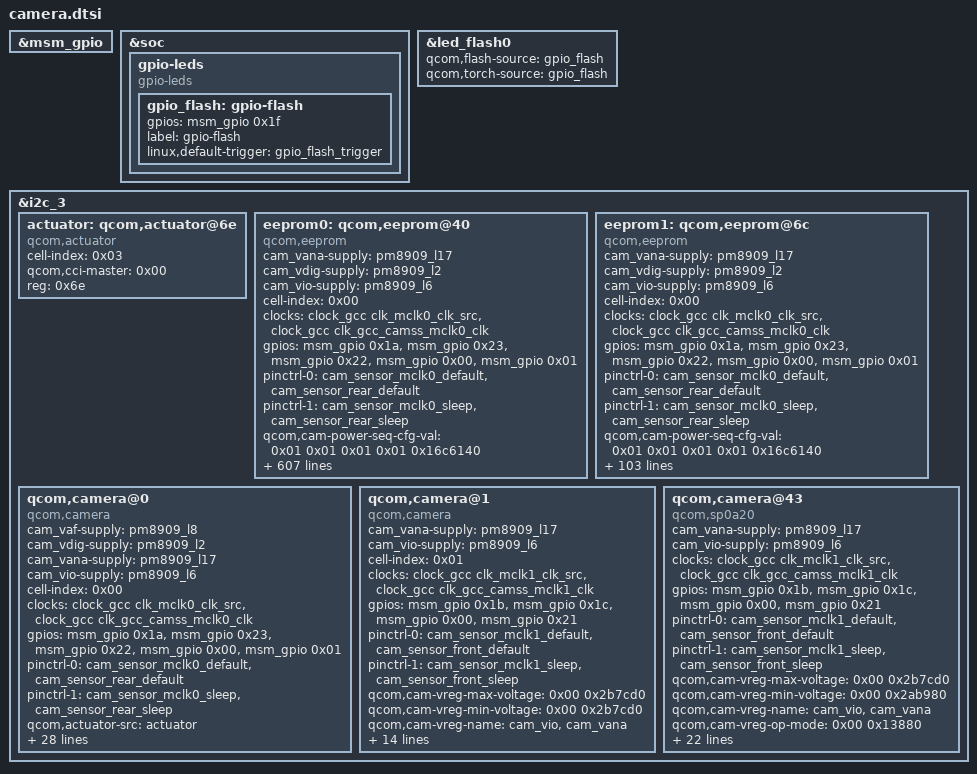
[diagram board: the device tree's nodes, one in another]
&msm_gpio {
	/delete-node/ SL610W1D_pins;
};

&soc {
	/delete-node/ flashlight;

	gpio-leds {
		compatible = "gpio-leds";
		status = "ok";

		gpio_flash: gpio-flash {
			gpios = <&msm_gpio 0x1f 0x00>;
			label = "gpio-flash";
			linux,default-trigger = "gpio_flash_trigger";
		};
	};
};

&led_flash0 {
	qcom,flash-source = <&gpio_flash>;
	qcom,torch-source = <&gpio_flash>;
};

&i2c_3 {
	/delete-node/ qcom,camera@0;
	/delete-node/ qcom,camera@1;
	/delete-node/ qcom,camera@42;

	actuator: qcom,actuator@6e {
		cell-index = <0x03>;
		compatible = "qcom,actuator";
		qcom,cci-master = <0x00>;
		reg = <0x6e>;
	};

	eeprom0: qcom,eeprom@40 {
		cam_vana-supply = <&pm8909_l17>;
		cam_vdig-supply = <&pm8909_l2>;
		cam_vio-supply = <&pm8909_l6>;
		cell-index = <0x00>;
		clock-names = "cam_src_clk", "cam_clk";
		clocks = <&clock_gcc clk_mclk0_clk_src>,
				<&clock_gcc clk_gcc_camss_mclk0_clk>;
		compatible = "qcom,eeprom";
		gpios = <&msm_gpio 0x1a 0x00 &msm_gpio 0x23 0x00 &msm_gpio 0x22 0x00 &msm_gpio 0x00 0x00 &msm_gpio 0x01 0x00>;
		pinctrl-0 = <&cam_sensor_mclk0_default
				&cam_sensor_rear_default>;
		pinctrl-1 = <&cam_sensor_mclk0_sleep &cam_sensor_rear_sleep>;
		pinctrl-names = "cam_default", "cam_suspend";
		qcom,cam-power-seq-cfg-val = <0x01 0x01 0x01 0x01 0x16c6140>;
		qcom,cam-power-seq-delay = <0x01 0x0a 0x0a 0x05 0x05>;
		qcom,cam-power-seq-type = "sensor_vreg", "sensor_gpio", "sensor_gpio", "sensor_gpio", "sensor_clk";
		qcom,cam-power-seq-val = "cam_vdig", "sensor_gpio_vana", "sensor_gpio_reset", "sensor_gpio_standby", "sensor_cam_mclk";
		qcom,cam-vreg-max-voltage = <0x124f80 0x00 0x2b7cd0>;
		qcom,cam-vreg-min-voltage = <0x124f80 0x00 0x2b7cd0>;
		qcom,cam-vreg-name = "cam_vdig", "cam_vio", "cam_vana";
		qcom,cam-vreg-op-mode = <0x30d40 0x00 0x13880>;
		qcom,cam-vreg-type = <0x00 0x01 0x00>;
		qcom,cci-master = <0x00>;
		qcom,eeprom-name = "hynix_hi841";
		qcom,gpio-req-tbl-flags = <0x01 0x00 0x00 0x00 0x00>;
		qcom,gpio-req-tbl-label = "CAMIF_MCLK", "CAM_RESET1", "CAM_STANDBY", "CAM_VANA", "CAM_VDIG";
		qcom,gpio-req-tbl-num = <0x00 0x01 0x02 0x03 0x04>;
		qcom,gpio-reset = <0x01>;
		qcom,gpio-standby = <0x02>;
		qcom,gpio-vana = <0x03>;
		qcom,gpio-vdig = <0x04>;
		qcom,mem0 = <0x00 0x00 0x02 0x00 0x01 0x00>;
		qcom,mem1 = <0x00 0x00 0x02 0x00 0x01 0x00>;
		qcom,mem10 = <0x01 0xa000 0x02 0x00 0x01 0x00>;
		qcom,mem100 = <0x00 0x00 0x02 0x00 0x01 0x00>;
		qcom,mem101 = <0x00 0x00 0x02 0x00 0x01 0x00>;
		qcom,mem102 = <0x00 0x00 0x02 0x00 0x01 0x00>;
		qcom,mem103 = <0x01 0xa000 0x02 0x00 0x01 0x00>;
		qcom,mem104 = <0x00 0x00 0x02 0x00 0x01 0x00>;
		qcom,mem105 = <0x00 0x00 0x02 0x00 0x01 0x00>;
		qcom,mem106 = <0x00 0x00 0x02 0x00 0x01 0x00>;
		qcom,mem107 = <0x01 0xa000 0x02 0x00 0x01 0x00>;
		qcom,mem108 = <0x00 0x00 0x02 0x00 0x01 0x00>;
		qcom,mem109 = <0x00 0x00 0x02 0x00 0x01 0x00>;
		qcom,mem11 = <0x00 0x00 0x02 0x00 0x01 0x00>;
		qcom,mem110 = <0x00 0x00 0x02 0x00 0x01 0x00>;
		qcom,mem111 = <0x01 0xa000 0x02 0x00 0x01 0x00>;
		qcom,mem112 = <0x00 0x00 0x02 0x00 0x01 0x00>;
		qcom,mem113 = <0x00 0x00 0x02 0x00 0x01 0x00>;
		qcom,mem114 = <0x00 0x00 0x02 0x00 0x01 0x00>;
		qcom,mem115 = <0x01 0xa000 0x02 0x00 0x01 0x00>;
		qcom,mem116 = <0x00 0x00 0x02 0x00 0x01 0x00>;
		qcom,mem117 = <0x00 0x00 0x02 0x00 0x01 0x00>;
		qcom,mem118 = <0x00 0x00 0x02 0x00 0x01 0x00>;
		qcom,mem119 = <0x01 0xa000 0x02 0x00 0x01 0x00>;
		qcom,mem12 = <0x00 0x00 0x02 0x00 0x01 0x00>;
		qcom,mem120 = <0x00 0x00 0x02 0x00 0x01 0x00>;
		qcom,mem121 = <0x00 0x00 0x02 0x00 0x01 0x00>;
		qcom,mem122 = <0x00 0x00 0x02 0x00 0x01 0x00>;
		qcom,mem123 = <0x01 0xa000 0x02 0x00 0x01 0x00>;
		qcom,mem124 = <0x00 0x00 0x02 0x00 0x01 0x00>;
		qcom,mem125 = <0x00 0x00 0x02 0x00 0x01 0x00>;
		qcom,mem126 = <0x00 0x00 0x02 0x00 0x01 0x00>;
		qcom,mem127 = <0x01 0xa000 0x02 0x00 0x01 0x00>;
		qcom,mem128 = <0x00 0x00 0x02 0x00 0x01 0x00>;
		qcom,mem129 = <0x00 0x00 0x02 0x00 0x01 0x00>;
		qcom,mem13 = <0x00 0x00 0x02 0x00 0x01 0x00>;
		qcom,mem130 = <0x00 0x00 0x02 0x00 0x01 0x00>;
		qcom,mem131 = <0x01 0xa000 0x02 0x00 0x01 0x00>;
		qcom,mem132 = <0x00 0x00 0x02 0x00 0x01 0x00>;
		qcom,mem133 = <0x00 0x00 0x02 0x00 0x01 0x00>;
		qcom,mem134 = <0x00 0x00 0x02 0x00 0x01 0x00>;
		qcom,mem135 = <0x01 0xa000 0x02 0x00 0x01 0x00>;
		qcom,mem136 = <0x00 0x00 0x02 0x00 0x01 0x00>;
		qcom,mem137 = <0x00 0x00 0x02 0x00 0x01 0x00>;
		qcom,mem138 = <0x00 0x00 0x02 0x00 0x01 0x00>;
		qcom,mem139 = <0x01 0xa000 0x02 0x00 0x01 0x00>;
		qcom,mem14 = <0x01 0xa000 0x02 0x00 0x01 0x00>;
		qcom,mem140 = <0x00 0x00 0x02 0x00 0x01 0x00>;
		qcom,mem141 = <0x00 0x00 0x02 0x00 0x01 0x00>;
		qcom,mem142 = <0x00 0x00 0x02 0x00 0x01 0x00>;
		qcom,mem143 = <0x01 0xa000 0x02 0x00 0x01 0x00>;
		qcom,mem144 = <0x00 0x00 0x02 0x00 0x01 0x00>;
		qcom,mem145 = <0x00 0x00 0x02 0x00 0x01 0x00>;
		qcom,mem146 = <0x00 0x00 0x02 0x00 0x01 0x00>;
		qcom,mem147 = <0x01 0xa000 0x02 0x00 0x01 0x00>;
		qcom,mem148 = <0x00 0x00 0x02 0x00 0x01 0x00>;
		qcom,mem149 = <0x00 0x00 0x02 0x00 0x01 0x00>;
		qcom,mem15 = <0x00 0x00 0x02 0x00 0x01 0x00>;
		qcom,mem150 = <0x00 0x00 0x02 0x00 0x01 0x00>;
		qcom,mem151 = <0x01 0xa000 0x02 0x00 0x01 0x00>;
		qcom,mem152 = <0x00 0x00 0x02 0x00 0x01 0x00>;
		qcom,mem153 = <0x00 0x00 0x02 0x00 0x01 0x00>;
		qcom,mem154 = <0x00 0x00 0x02 0x00 0x01 0x00>;
		qcom,mem155 = <0x01 0xa000 0x02 0x00 0x01 0x00>;
		qcom,mem156 = <0x00 0x00 0x02 0x00 0x01 0x00>;
		qcom,mem157 = <0x00 0x00 0x02 0x00 0x01 0x00>;
		qcom,mem158 = <0x00 0x00 0x02 0x00 0x01 0x00>;
		qcom,mem159 = <0x01 0xa000 0x02 0x00 0x01 0x00>;
		qcom,mem16 = <0x00 0x00 0x02 0x00 0x01 0x00>;
		qcom,mem160 = <0x00 0x00 0x02 0x00 0x01 0x00>;
		qcom,mem161 = <0x00 0x00 0x02 0x00 0x01 0x00>;
		qcom,mem162 = <0x00 0x00 0x02 0x00 0x01 0x00>;
		qcom,mem163 = <0x01 0xa000 0x02 0x00 0x01 0x00>;
		qcom,mem164 = <0x00 0x00 0x02 0x00 0x01 0x00>;
		qcom,mem165 = <0x00 0x00 0x02 0x00 0x01 0x00>;
		qcom,mem166 = <0x00 0x00 0x02 0x00 0x01 0x00>;
		qcom,mem167 = <0x01 0xa000 0x02 0x00 0x01 0x00>;
		qcom,mem168 = <0x00 0x00 0x02 0x00 0x01 0x00>;
		qcom,mem169 = <0x00 0x00 0x02 0x00 0x01 0x00>;
		qcom,mem17 = <0x01 0xa000 0x02 0x00 0x01 0x00>;
		qcom,mem170 = <0x00 0x00 0x02 0x00 0x01 0x00>;
		qcom,mem171 = <0x01 0xa000 0x02 0x00 0x01 0x00>;
		qcom,mem172 = <0x00 0x00 0x02 0x00 0x01 0x00>;
		qcom,mem173 = <0x00 0x00 0x02 0x00 0x01 0x00>;
		qcom,mem174 = <0x00 0x00 0x02 0x00 0x01 0x00>;
		qcom,mem175 = <0x01 0xa000 0x02 0x00 0x01 0x00>;
		qcom,mem176 = <0x00 0x00 0x02 0x00 0x01 0x00>;
		qcom,mem177 = <0x00 0x00 0x02 0x00 0x01 0x00>;
		qcom,mem178 = <0x00 0x00 0x02 0x00 0x01 0x00>;
		qcom,mem179 = <0x01 0xa000 0x02 0x00 0x01 0x00>;
		qcom,mem18 = <0x00 0x00 0x02 0x00 0x01 0x00>;
		qcom,mem180 = <0x00 0x00 0x02 0x00 0x01 0x00>;
		qcom,mem181 = <0x00 0x00 0x02 0x00 0x01 0x00>;
		qcom,mem182 = <0x00 0x00 0x02 0x00 0x01 0x00>;
		qcom,mem183 = <0x01 0xa000 0x02 0x00 0x01 0x00>;
		qcom,mem184 = <0x00 0x00 0x02 0x00 0x01 0x00>;
		qcom,mem185 = <0x00 0x00 0x02 0x00 0x01 0x00>;
		qcom,mem186 = <0x00 0x00 0x02 0x00 0x01 0x00>;
		qcom,mem187 = <0x01 0xa000 0x02 0x00 0x01 0x00>;
		qcom,mem188 = <0x00 0x00 0x02 0x00 0x01 0x00>;
		qcom,mem189 = <0x00 0x00 0x02 0x00 0x01 0x00>;
		qcom,mem19 = <0x00 0x00 0x02 0x00 0x01 0x00>;
		qcom,mem190 = <0x00 0x00 0x02 0x00 0x01 0x00>;
		qcom,mem191 = <0x01 0xa000 0x02 0x00 0x01 0x00>;
		qcom,mem2 = <0x00 0x00 0x02 0x00 0x01 0x00>;
		qcom,mem20 = <0x00 0x00 0x02 0x00 0x01 0x00>;
		qcom,mem21 = <0x01 0xa000 0x02 0x00 0x01 0x00>;
		qcom,mem22 = <0x00 0x00 0x02 0x00 0x01 0x00>;
		qcom,mem23 = <0x00 0x00 0x02 0x00 0x01 0x00>;
		qcom,mem24 = <0x01 0xa000 0x02 0x00 0x01 0x00>;
		qcom,mem25 = <0x00 0x00 0x02 0x00 0x01 0x00>;
		qcom,mem26 = <0x00 0x00 0x02 0x00 0x01 0x00>;
		qcom,mem27 = <0x00 0x00 0x02 0x00 0x01 0x00>;
		qcom,mem28 = <0x01 0xa000 0x02 0x00 0x01 0x00>;
		qcom,mem29 = <0x00 0x00 0x02 0x00 0x01 0x00>;
		qcom,mem3 = <0x01 0xa000 0x02 0x00 0x01 0x00>;
		qcom,mem30 = <0x00 0x00 0x02 0x00 0x01 0x00>;
		qcom,mem31 = <0x01 0xa000 0x02 0x00 0x01 0x00>;
		qcom,mem32 = <0x00 0x00 0x02 0x00 0x01 0x00>;
		qcom,mem33 = <0x00 0x00 0x02 0x00 0x01 0x00>;
		qcom,mem34 = <0x00 0x00 0x02 0x00 0x01 0x00>;
		qcom,mem35 = <0x01 0xa000 0x02 0x00 0x01 0x00>;
		qcom,mem36 = <0x00 0x00 0x02 0x00 0x01 0x00>;
		qcom,mem37 = <0x00 0x00 0x02 0x00 0x01 0x00>;
		qcom,mem38 = <0x01 0xa000 0x02 0x00 0x01 0x00>;
		qcom,mem39 = <0x00 0x00 0x02 0x00 0x01 0x00>;
		qcom,mem4 = <0x00 0x00 0x02 0x00 0x01 0x00>;
		qcom,mem40 = <0x00 0x00 0x02 0x00 0x01 0x00>;
		qcom,mem41 = <0x00 0x00 0x02 0x00 0x01 0x00>;
		qcom,mem42 = <0x01 0xa000 0x02 0x00 0x01 0x00>;
		qcom,mem43 = <0x00 0x00 0x02 0x00 0x01 0x00>;
		qcom,mem44 = <0x00 0x00 0x02 0x00 0x01 0x00>;
		qcom,mem45 = <0x01 0xa000 0x02 0x00 0x01 0x00>;
		qcom,mem46 = <0x00 0x00 0x02 0x00 0x01 0x00>;
		qcom,mem47 = <0x00 0x00 0x02 0x00 0x01 0x00>;
		qcom,mem48 = <0x00 0x00 0x02 0x00 0x01 0x00>;
		qcom,mem49 = <0x01 0xa000 0x02 0x00 0x01 0x00>;
		qcom,mem5 = <0x00 0x00 0x02 0x00 0x01 0x00>;
		qcom,mem50 = <0x00 0x00 0x02 0x00 0x01 0x00>;
		qcom,mem51 = <0x00 0x00 0x02 0x00 0x01 0x00>;
		qcom,mem52 = <0x01 0xa000 0x02 0x00 0x01 0x00>;
		qcom,mem53 = <0x00 0x00 0x02 0x00 0x01 0x00>;
		qcom,mem54 = <0x00 0x00 0x02 0x00 0x01 0x00>;
		qcom,mem55 = <0x00 0x00 0x02 0x00 0x01 0x00>;
		qcom,mem56 = <0x01 0xa000 0x02 0x00 0x01 0x00>;
		qcom,mem57 = <0x00 0x00 0x02 0x00 0x01 0x00>;
		qcom,mem58 = <0x00 0x00 0x02 0x00 0x01 0x00>;
		qcom,mem59 = <0x01 0xa000 0x02 0x00 0x01 0x00>;
		qcom,mem6 = <0x00 0x00 0x02 0x00 0x01 0x00>;
		qcom,mem60 = <0x00 0x00 0x02 0x00 0x01 0x00>;
		qcom,mem61 = <0x00 0x00 0x02 0x00 0x01 0x00>;
		qcom,mem62 = <0x00 0x00 0x02 0x00 0x01 0x00>;
		qcom,mem63 = <0x01 0xa000 0x02 0x00 0x01 0x00>;
		qcom,mem64 = <0x00 0x00 0x02 0x00 0x01 0x00>;
		qcom,mem65 = <0x00 0x00 0x02 0x00 0x01 0x00>;
		qcom,mem66 = <0x01 0xa000 0x02 0x00 0x01 0x00>;
		qcom,mem67 = <0x00 0x00 0x02 0x00 0x01 0x00>;
		qcom,mem68 = <0x00 0x00 0x02 0x00 0x01 0x00>;
		qcom,mem69 = <0x00 0x00 0x02 0x00 0x01 0x00>;
		qcom,mem7 = <0x01 0xa000 0x02 0x00 0x01 0x00>;
		qcom,mem70 = <0x01 0xa000 0x02 0x00 0x01 0x00>;
		qcom,mem71 = <0x00 0x00 0x02 0x00 0x01 0x00>;
		qcom,mem72 = <0x00 0x00 0x02 0x00 0x01 0x00>;
		qcom,mem73 = <0x01 0xa000 0x02 0x00 0x01 0x00>;
		qcom,mem74 = <0x00 0x00 0x02 0x00 0x01 0x00>;
		qcom,mem75 = <0x00 0x00 0x02 0x00 0x01 0x00>;
		qcom,mem76 = <0x00 0x00 0x02 0x00 0x01 0x00>;
		qcom,mem77 = <0x01 0xa000 0x02 0x00 0x01 0x00>;
		qcom,mem78 = <0x00 0x00 0x02 0x00 0x01 0x00>;
		qcom,mem79 = <0x00 0x00 0x02 0x00 0x01 0x00>;
		qcom,mem8 = <0x00 0x00 0x02 0x00 0x01 0x00>;
		qcom,mem80 = <0x01 0xa000 0x02 0x00 0x01 0x00>;
		qcom,mem81 = <0x00 0x00 0x02 0x00 0x01 0x00>;
		qcom,mem82 = <0x00 0x00 0x02 0x00 0x01 0x00>;
		qcom,mem83 = <0x00 0x00 0x02 0x00 0x01 0x00>;
		qcom,mem84 = <0x01 0xa000 0x02 0x00 0x01 0x00>;
		qcom,mem85 = <0x00 0x00 0x02 0x00 0x01 0x00>;
		qcom,mem86 = <0x00 0x00 0x02 0x00 0x01 0x00>;
		qcom,mem87 = <0x01 0xa000 0x02 0x00 0x01 0x00>;
		qcom,mem88 = <0x00 0x00 0x02 0x00 0x01 0x00>;
		qcom,mem89 = <0x00 0x00 0x02 0x00 0x01 0x00>;
		qcom,mem9 = <0x00 0x00 0x02 0x00 0x01 0x00>;
		qcom,mem90 = <0x00 0x00 0x02 0x00 0x01 0x00>;
		qcom,mem91 = <0x01 0xa000 0x02 0x00 0x01 0x00>;
		qcom,mem92 = <0x00 0x00 0x02 0x00 0x01 0x00>;
		qcom,mem93 = <0x00 0x00 0x02 0x00 0x01 0x00>;
		qcom,mem94 = <0x00 0x00 0x02 0x00 0x01 0x00>;
		qcom,mem95 = <0x01 0xa000 0x02 0x00 0x01 0x00>;
		qcom,mem96 = <0x00 0x00 0x02 0x00 0x01 0x00>;
		qcom,mem97 = <0x00 0x00 0x02 0x00 0x01 0x00>;
		qcom,mem98 = <0x00 0x00 0x02 0x00 0x01 0x00>;
		qcom,mem99 = <0x01 0xa000 0x02 0x00 0x01 0x00>;
		qcom,num-blocks = <0xc0>;
		qcom,page0 = <0x01 0x8400 0x02 0x03 0x01 0x01>;
		qcom,page1 = <0x01 0x9c04 0x02 0xbc 0x01 0x01>;
		qcom,page10 = <0x01 0x9c00 0x02 0x11 0x01 0x01>;
		qcom,page100 = <0x01 0x8400 0x02 0x03 0x01 0x01>;
		qcom,page101 = <0x01 0x9c04 0x02 0xbc 0x01 0x01>;
		qcom,page102 = <0x01 0x9c05 0x02 0xef 0x01 0x01>;
		qcom,page103 = <0x01 0x9c00 0x02 0x11 0x01 0x01>;
		qcom,page104 = <0x01 0x8400 0x02 0x03 0x01 0x01>;
		qcom,page105 = <0x01 0x9c04 0x02 0xbc 0x01 0x01>;
		qcom,page106 = <0x01 0x9c05 0x02 0xf0 0x01 0x01>;
		qcom,page107 = <0x01 0x9c00 0x02 0x11 0x01 0x01>;
		qcom,page108 = <0x01 0x8400 0x02 0x03 0x01 0x01>;
		qcom,page109 = <0x01 0x9c04 0x02 0xbc 0x01 0x01>;
		qcom,page11 = <0x01 0x8400 0x02 0x03 0x01 0x01>;
		qcom,page110 = <0x01 0x9c05 0x02 0xf1 0x01 0x01>;
		qcom,page111 = <0x01 0x9c00 0x02 0x11 0x01 0x01>;
		qcom,page112 = <0x01 0x8400 0x02 0x03 0x01 0x01>;
		qcom,page113 = <0x01 0x9c04 0x02 0xbc 0x01 0x01>;
		qcom,page114 = <0x01 0x9c05 0x02 0xf2 0x01 0x01>;
		qcom,page115 = <0x01 0x9c00 0x02 0x11 0x01 0x01>;
		qcom,page116 = <0x01 0x8400 0x02 0x03 0x01 0x01>;
		qcom,page117 = <0x01 0x9c04 0x02 0xbc 0x01 0x01>;
		qcom,page118 = <0x01 0x9c05 0x02 0xf0 0x01 0x01>;
		qcom,page119 = <0x01 0x9c00 0x02 0x11 0x01 0x01>;
		qcom,page12 = <0x01 0x9c04 0x02 0xbd 0x01 0x01>;
		qcom,page120 = <0x01 0x8400 0x02 0x03 0x01 0x01>;
		qcom,page121 = <0x01 0x9c04 0x02 0xbc 0x01 0x01>;
		qcom,page122 = <0x01 0x9c05 0x02 0xf1 0x01 0x01>;
		qcom,page123 = <0x01 0x9c00 0x02 0x11 0x01 0x01>;
		qcom,page124 = <0x01 0x8400 0x02 0x03 0x01 0x01>;
		qcom,page125 = <0x01 0x9c04 0x02 0xbc 0x01 0x01>;
		qcom,page126 = <0x01 0x9c05 0x02 0xf2 0x01 0x01>;
		qcom,page127 = <0x01 0x9c00 0x02 0x11 0x01 0x01>;
		qcom,page128 = <0x01 0x8400 0x02 0x03 0x01 0x01>;
		qcom,page129 = <0x01 0x9c04 0x02 0xbd 0x01 0x01>;
		qcom,page13 = <0x01 0x9c05 0x02 0x01 0x01 0x01>;
		qcom,page130 = <0x01 0x9c05 0x02 0x27 0x01 0x01>;
		qcom,page131 = <0x01 0x9c00 0x02 0x11 0x01 0x01>;
		qcom,page132 = <0x01 0x8400 0x02 0x03 0x01 0x01>;
		qcom,page133 = <0x01 0x9c04 0x02 0xbd 0x01 0x01>;
		qcom,page134 = <0x01 0x9c05 0x02 0x2d 0x01 0x01>;
		qcom,page135 = <0x01 0x9c00 0x02 0x11 0x01 0x01>;
		qcom,page136 = <0x01 0x8400 0x02 0x03 0x01 0x01>;
		qcom,page137 = <0x01 0x9c04 0x02 0xbd 0x01 0x01>;
		qcom,page138 = <0x01 0x9c05 0x02 0x29 0x01 0x01>;
		qcom,page139 = <0x01 0x9c00 0x02 0x11 0x01 0x01>;
		qcom,page14 = <0x01 0x9c00 0x02 0x11 0x01 0x01>;
		qcom,page140 = <0x01 0x8400 0x02 0x03 0x01 0x01>;
		qcom,page141 = <0x01 0x9c04 0x02 0xbd 0x01 0x01>;
		qcom,page142 = <0x01 0x9c05 0x02 0x2a 0x01 0x01>;
		qcom,page143 = <0x01 0x9c00 0x02 0x11 0x01 0x01>;
		qcom,page144 = <0x01 0x8400 0x02 0x03 0x01 0x01>;
		qcom,page145 = <0x01 0x9c04 0x02 0xbd 0x01 0x01>;
		qcom,page146 = <0x01 0x9c05 0x02 0x2b 0x01 0x01>;
		qcom,page147 = <0x01 0x9c00 0x02 0x11 0x01 0x01>;
		qcom,page148 = <0x01 0x8400 0x02 0x03 0x01 0x01>;
		qcom,page149 = <0x01 0x9c04 0x02 0xbd 0x01 0x01>;
		qcom,page15 = <0x01 0x9c04 0x02 0xbd 0x01 0x01>;
		qcom,page150 = <0x01 0x9c05 0x02 0x29 0x01 0x01>;
		qcom,page151 = <0x01 0x9c00 0x02 0x11 0x01 0x01>;
		qcom,page152 = <0x01 0x8400 0x02 0x03 0x01 0x01>;
		qcom,page153 = <0x01 0x9c04 0x02 0xbd 0x01 0x01>;
		qcom,page154 = <0x01 0x9c05 0x02 0x2a 0x01 0x01>;
		qcom,page155 = <0x01 0x9c00 0x02 0x11 0x01 0x01>;
		qcom,page156 = <0x01 0x8400 0x02 0x03 0x01 0x01>;
		qcom,page157 = <0x01 0x9c04 0x02 0xbd 0x01 0x01>;
		qcom,page158 = <0x01 0x9c05 0x02 0x2b 0x01 0x01>;
		qcom,page159 = <0x01 0x9c00 0x02 0x11 0x01 0x01>;
		qcom,page16 = <0x01 0x9c05 0x02 0x02 0x01 0x01>;
		qcom,page160 = <0x01 0x8400 0x02 0x03 0x01 0x01>;
		qcom,page161 = <0x01 0x9c04 0x02 0xbd 0x01 0x01>;
		qcom,page162 = <0x01 0x9c05 0x02 0x60 0x01 0x01>;
		qcom,page163 = <0x01 0x9c00 0x02 0x11 0x01 0x01>;
		qcom,page164 = <0x01 0x8400 0x02 0x03 0x01 0x01>;
		qcom,page165 = <0x01 0x9c04 0x02 0xbd 0x01 0x01>;
		qcom,page166 = <0x01 0x9c05 0x02 0x66 0x01 0x01>;
		qcom,page167 = <0x01 0x9c00 0x02 0x11 0x01 0x01>;
		qcom,page168 = <0x01 0x8400 0x02 0x03 0x01 0x01>;
		qcom,page169 = <0x01 0x9c04 0x02 0xbd 0x01 0x01>;
		qcom,page17 = <0x01 0x9c00 0x02 0x11 0x01 0x01>;
		qcom,page170 = <0x01 0x9c05 0x02 0x62 0x01 0x01>;
		qcom,page171 = <0x01 0x9c00 0x02 0x11 0x01 0x01>;
		qcom,page172 = <0x01 0x8400 0x02 0x03 0x01 0x01>;
		qcom,page173 = <0x01 0x9c04 0x02 0xbd 0x01 0x01>;
		qcom,page174 = <0x01 0x9c05 0x02 0x63 0x01 0x01>;
		qcom,page175 = <0x01 0x9c00 0x02 0x11 0x01 0x01>;
		qcom,page176 = <0x01 0x8400 0x02 0x03 0x01 0x01>;
		qcom,page177 = <0x01 0x9c04 0x02 0xbd 0x01 0x01>;
		qcom,page178 = <0x01 0x9c05 0x02 0x64 0x01 0x01>;
		qcom,page179 = <0x01 0x9c00 0x02 0x11 0x01 0x01>;
		qcom,page18 = <0x01 0x8400 0x02 0x03 0x01 0x01>;
		qcom,page180 = <0x01 0x8400 0x02 0x03 0x01 0x01>;
		qcom,page181 = <0x01 0x9c04 0x02 0xbd 0x01 0x01>;
		qcom,page182 = <0x01 0x9c05 0x02 0x62 0x01 0x01>;
		qcom,page183 = <0x01 0x9c00 0x02 0x11 0x01 0x01>;
		qcom,page184 = <0x01 0x8400 0x02 0x03 0x01 0x01>;
		qcom,page185 = <0x01 0x9c04 0x02 0xbd 0x01 0x01>;
		qcom,page186 = <0x01 0x9c05 0x02 0x63 0x01 0x01>;
		qcom,page187 = <0x01 0x9c00 0x02 0x11 0x01 0x01>;
		qcom,page188 = <0x01 0x8400 0x02 0x03 0x01 0x01>;
		qcom,page189 = <0x01 0x9c04 0x02 0xbd 0x01 0x01>;
		qcom,page19 = <0x01 0x9c04 0x02 0xbd 0x01 0x01>;
		qcom,page190 = <0x01 0x9c05 0x02 0x64 0x01 0x01>;
		qcom,page191 = <0x01 0x9c00 0x02 0x11 0x01 0x01>;
		qcom,page2 = <0x01 0x9c05 0x02 0xeb 0x01 0x01>;
		qcom,page20 = <0x01 0x9c05 0x02 0x05 0x01 0x01>;
		qcom,page21 = <0x01 0x9c00 0x02 0x11 0x01 0x01>;
		qcom,page22 = <0x01 0x9c04 0x02 0xbd 0x01 0x01>;
		qcom,page23 = <0x01 0x9c05 0x02 0x06 0x01 0x01>;
		qcom,page24 = <0x01 0x9c00 0x02 0x11 0x01 0x01>;
		qcom,page25 = <0x01 0x8400 0x02 0x03 0x01 0x01>;
		qcom,page26 = <0x01 0x9c04 0x02 0xbd 0x01 0x01>;
		qcom,page27 = <0x01 0x9c05 0x02 0x07 0x01 0x01>;
		qcom,page28 = <0x01 0x9c00 0x02 0x11 0x01 0x01>;
		qcom,page29 = <0x01 0x9c04 0x02 0xbd 0x01 0x01>;
		qcom,page3 = <0x01 0x9c00 0x02 0x11 0x01 0x01>;
		qcom,page30 = <0x01 0x9c05 0x02 0x08 0x01 0x01>;
		qcom,page31 = <0x01 0x9c00 0x02 0x11 0x01 0x01>;
		qcom,page32 = <0x01 0x8400 0x02 0x03 0x01 0x01>;
		qcom,page33 = <0x01 0x9c04 0x02 0xbd 0x01 0x01>;
		qcom,page34 = <0x01 0x9c05 0x02 0x71 0x01 0x01>;
		qcom,page35 = <0x01 0x9c00 0x02 0x11 0x01 0x01>;
		qcom,page36 = <0x01 0x9c04 0x02 0xbd 0x01 0x01>;
		qcom,page37 = <0x01 0x9c05 0x02 0x72 0x01 0x01>;
		qcom,page38 = <0x01 0x9c00 0x02 0x11 0x01 0x01>;
		qcom,page39 = <0x01 0x8400 0x02 0x03 0x01 0x01>;
		qcom,page4 = <0x01 0x8400 0x02 0x03 0x01 0x01>;
		qcom,page40 = <0x01 0x9c04 0x02 0xbd 0x01 0x01>;
		qcom,page41 = <0x01 0x9c05 0x02 0x73 0x01 0x01>;
		qcom,page42 = <0x01 0x9c00 0x02 0x11 0x01 0x01>;
		qcom,page43 = <0x01 0x9c04 0x02 0xbd 0x01 0x01>;
		qcom,page44 = <0x01 0x9c05 0x02 0x74 0x01 0x01>;
		qcom,page45 = <0x01 0x9c00 0x02 0x11 0x01 0x01>;
		qcom,page46 = <0x01 0x8400 0x02 0x03 0x01 0x01>;
		qcom,page47 = <0x01 0x9c04 0x02 0xbd 0x01 0x01>;
		qcom,page48 = <0x01 0x9c05 0x02 0x77 0x01 0x01>;
		qcom,page49 = <0x01 0x9c00 0x02 0x11 0x01 0x01>;
		qcom,page5 = <0x01 0x9c04 0x02 0xbc 0x01 0x01>;
		qcom,page50 = <0x01 0x9c04 0x02 0xbd 0x01 0x01>;
		qcom,page51 = <0x01 0x9c05 0x02 0x78 0x01 0x01>;
		qcom,page52 = <0x01 0x9c00 0x02 0x11 0x01 0x01>;
		qcom,page53 = <0x01 0x8400 0x02 0x03 0x01 0x01>;
		qcom,page54 = <0x01 0x9c04 0x02 0xbd 0x01 0x01>;
		qcom,page55 = <0x01 0x9c05 0x02 0x79 0x01 0x01>;
		qcom,page56 = <0x01 0x9c00 0x02 0x11 0x01 0x01>;
		qcom,page57 = <0x01 0x9c04 0x02 0xbd 0x01 0x01>;
		qcom,page58 = <0x01 0x9c05 0x02 0x7a 0x01 0x01>;
		qcom,page59 = <0x01 0x9c00 0x02 0x11 0x01 0x01>;
		qcom,page6 = <0x01 0x9c05 0x02 0xff 0x01 0x01>;
		qcom,page60 = <0x01 0x8400 0x02 0x03 0x01 0x01>;
		qcom,page61 = <0x01 0x9c04 0x02 0xbd 0x01 0x01>;
		qcom,page62 = <0x01 0x9c05 0x02 0x38 0x01 0x01>;
		qcom,page63 = <0x01 0x9c00 0x02 0x11 0x01 0x01>;
		qcom,page64 = <0x01 0x9c04 0x02 0xbd 0x01 0x01>;
		qcom,page65 = <0x01 0x9c05 0x02 0x39 0x01 0x01>;
		qcom,page66 = <0x01 0x9c00 0x02 0x11 0x01 0x01>;
		qcom,page67 = <0x01 0x8400 0x02 0x03 0x01 0x01>;
		qcom,page68 = <0x01 0x9c04 0x02 0xbd 0x01 0x01>;
		qcom,page69 = <0x01 0x9c05 0x02 0x3a 0x01 0x01>;
		qcom,page7 = <0x01 0x9c00 0x02 0x11 0x01 0x01>;
		qcom,page70 = <0x01 0x9c00 0x02 0x11 0x01 0x01>;
		qcom,page71 = <0x01 0x9c04 0x02 0xbd 0x01 0x01>;
		qcom,page72 = <0x01 0x9c05 0x02 0x3b 0x01 0x01>;
		qcom,page73 = <0x01 0x9c00 0x02 0x11 0x01 0x01>;
		qcom,page74 = <0x01 0x8400 0x02 0x03 0x01 0x01>;
		qcom,page75 = <0x01 0x9c04 0x02 0xbd 0x01 0x01>;
		qcom,page76 = <0x01 0x9c05 0x02 0x3e 0x01 0x01>;
		qcom,page77 = <0x01 0x9c00 0x02 0x11 0x01 0x01>;
		qcom,page78 = <0x01 0x9c04 0x02 0xbd 0x01 0x01>;
		qcom,page79 = <0x01 0x9c05 0x02 0x3f 0x01 0x01>;
		qcom,page8 = <0x01 0x9c04 0x02 0xbd 0x01 0x01>;
		qcom,page80 = <0x01 0x9c00 0x02 0x11 0x01 0x01>;
		qcom,page81 = <0x01 0x8400 0x02 0x03 0x01 0x01>;
		qcom,page82 = <0x01 0x9c04 0x02 0xbd 0x01 0x01>;
		qcom,page83 = <0x01 0x9c05 0x02 0x40 0x01 0x01>;
		qcom,page84 = <0x01 0x9c00 0x02 0x11 0x01 0x01>;
		qcom,page85 = <0x01 0x9c04 0x02 0xbd 0x01 0x01>;
		qcom,page86 = <0x01 0x9c05 0x02 0x41 0x01 0x01>;
		qcom,page87 = <0x01 0x9c00 0x02 0x11 0x01 0x01>;
		qcom,page88 = <0x01 0x8400 0x02 0x03 0x01 0x01>;
		qcom,page89 = <0x01 0x9c04 0x02 0xbc 0x01 0x01>;
		qcom,page9 = <0x01 0x9c05 0x02 0x00 0x01 0x01>;
		qcom,page90 = <0x01 0x9c05 0x02 0xed 0x01 0x01>;
		qcom,page91 = <0x01 0x9c00 0x02 0x11 0x01 0x01>;
		qcom,page92 = <0x01 0x8400 0x02 0x03 0x01 0x01>;
		qcom,page93 = <0x01 0x9c04 0x02 0xbc 0x01 0x01>;
		qcom,page94 = <0x01 0x9c05 0x02 0xea 0x01 0x01>;
		qcom,page95 = <0x01 0x9c00 0x02 0x11 0x01 0x01>;
		qcom,page96 = <0x01 0x8400 0x02 0x03 0x01 0x01>;
		qcom,page97 = <0x01 0x9c04 0x02 0xbc 0x01 0x01>;
		qcom,page98 = <0x01 0x9c05 0x02 0xee 0x01 0x01>;
		qcom,page99 = <0x01 0x9c00 0x02 0x11 0x01 0x01>;
		qcom,poll0 = <0x00 0x00 0x02 0x00 0x01 0x01>;
		qcom,poll1 = <0x00 0x00 0x02 0x00 0x01 0x01>;
		qcom,poll10 = <0x00 0x00 0x02 0x00 0x01 0x01>;
		qcom,poll100 = <0x00 0x00 0x02 0x00 0x01 0x01>;
		qcom,poll101 = <0x00 0x00 0x02 0x00 0x01 0x01>;
		qcom,poll102 = <0x00 0x00 0x02 0x00 0x01 0x01>;
		qcom,poll103 = <0x00 0x00 0x02 0x00 0x01 0x01>;
		qcom,poll104 = <0x00 0x00 0x02 0x00 0x01 0x01>;
		qcom,poll105 = <0x00 0x00 0x02 0x00 0x01 0x01>;
		qcom,poll106 = <0x00 0x00 0x02 0x00 0x01 0x01>;
		qcom,poll107 = <0x00 0x00 0x02 0x00 0x01 0x01>;
		qcom,poll108 = <0x00 0x00 0x02 0x00 0x01 0x01>;
		qcom,poll109 = <0x00 0x00 0x02 0x00 0x01 0x01>;
		qcom,poll11 = <0x00 0x00 0x02 0x00 0x01 0x01>;
		qcom,poll110 = <0x00 0x00 0x02 0x00 0x01 0x01>;
		qcom,poll111 = <0x00 0x00 0x02 0x00 0x01 0x01>;
		qcom,poll112 = <0x00 0x00 0x02 0x00 0x01 0x01>;
		qcom,poll113 = <0x00 0x00 0x02 0x00 0x01 0x01>;
		qcom,poll114 = <0x00 0x00 0x02 0x00 0x01 0x01>;
		qcom,poll115 = <0x00 0x00 0x02 0x00 0x01 0x01>;
		qcom,poll116 = <0x00 0x00 0x02 0x00 0x01 0x01>;
		qcom,poll117 = <0x00 0x00 0x02 0x00 0x01 0x01>;
		qcom,poll118 = <0x00 0x00 0x02 0x00 0x01 0x01>;
		qcom,poll119 = <0x00 0x00 0x02 0x00 0x01 0x01>;
		qcom,poll12 = <0x00 0x00 0x02 0x00 0x01 0x01>;
		qcom,poll120 = <0x00 0x00 0x02 0x00 0x01 0x01>;
		qcom,poll121 = <0x00 0x00 0x02 0x00 0x01 0x01>;
		qcom,poll122 = <0x00 0x00 0x02 0x00 0x01 0x01>;
		qcom,poll123 = <0x00 0x00 0x02 0x00 0x01 0x01>;
		qcom,poll124 = <0x00 0x00 0x02 0x00 0x01 0x01>;
		qcom,poll125 = <0x00 0x00 0x02 0x00 0x01 0x01>;
		qcom,poll126 = <0x00 0x00 0x02 0x00 0x01 0x01>;
		qcom,poll127 = <0x00 0x00 0x02 0x00 0x01 0x01>;
		qcom,poll128 = <0x00 0x00 0x02 0x00 0x01 0x01>;
		qcom,poll129 = <0x00 0x00 0x02 0x00 0x01 0x01>;
		qcom,poll13 = <0x00 0x00 0x02 0x00 0x01 0x01>;
		qcom,poll130 = <0x00 0x00 0x02 0x00 0x01 0x01>;
		qcom,poll131 = <0x00 0x00 0x02 0x00 0x01 0x01>;
		qcom,poll132 = <0x00 0x00 0x02 0x00 0x01 0x01>;
		qcom,poll133 = <0x00 0x00 0x02 0x00 0x01 0x01>;
		qcom,poll134 = <0x00 0x00 0x02 0x00 0x01 0x01>;
		qcom,poll135 = <0x00 0x00 0x02 0x00 0x01 0x01>;
		qcom,poll136 = <0x00 0x00 0x02 0x00 0x01 0x01>;
		qcom,poll137 = <0x00 0x00 0x02 0x00 0x01 0x01>;
		qcom,poll138 = <0x00 0x00 0x02 0x00 0x01 0x01>;
		qcom,poll139 = <0x00 0x00 0x02 0x00 0x01 0x01>;
		qcom,poll14 = <0x00 0x00 0x02 0x00 0x01 0x01>;
		qcom,poll140 = <0x00 0x00 0x02 0x00 0x01 0x01>;
		qcom,poll141 = <0x00 0x00 0x02 0x00 0x01 0x01>;
		qcom,poll142 = <0x00 0x00 0x02 0x00 0x01 0x01>;
		qcom,poll143 = <0x00 0x00 0x02 0x00 0x01 0x01>;
		qcom,poll144 = <0x00 0x00 0x02 0x00 0x01 0x01>;
		qcom,poll145 = <0x00 0x00 0x02 0x00 0x01 0x01>;
		qcom,poll146 = <0x00 0x00 0x02 0x00 0x01 0x01>;
		qcom,poll147 = <0x00 0x00 0x02 0x00 0x01 0x01>;
		qcom,poll148 = <0x00 0x00 0x02 0x00 0x01 0x01>;
		qcom,poll149 = <0x00 0x00 0x02 0x00 0x01 0x01>;
		qcom,poll15 = <0x00 0x00 0x02 0x00 0x01 0x01>;
		qcom,poll150 = <0x00 0x00 0x02 0x00 0x01 0x01>;
		qcom,poll151 = <0x00 0x00 0x02 0x00 0x01 0x01>;
		qcom,poll152 = <0x00 0x00 0x02 0x00 0x01 0x01>;
		qcom,poll153 = <0x00 0x00 0x02 0x00 0x01 0x01>;
		qcom,poll154 = <0x00 0x00 0x02 0x00 0x01 0x01>;
		qcom,poll155 = <0x00 0x00 0x02 0x00 0x01 0x01>;
		qcom,poll156 = <0x00 0x00 0x02 0x00 0x01 0x01>;
		qcom,poll157 = <0x00 0x00 0x02 0x00 0x01 0x01>;
		qcom,poll158 = <0x00 0x00 0x02 0x00 0x01 0x01>;
		qcom,poll159 = <0x00 0x00 0x02 0x00 0x01 0x01>;
		qcom,poll16 = <0x00 0x00 0x02 0x00 0x01 0x01>;
		qcom,poll160 = <0x00 0x00 0x02 0x00 0x01 0x01>;
		qcom,poll161 = <0x00 0x00 0x02 0x00 0x01 0x01>;
		qcom,poll162 = <0x00 0x00 0x02 0x00 0x01 0x01>;
		qcom,poll163 = <0x00 0x00 0x02 0x00 0x01 0x01>;
		qcom,poll164 = <0x00 0x00 0x02 0x00 0x01 0x01>;
		qcom,poll165 = <0x00 0x00 0x02 0x00 0x01 0x01>;
		qcom,poll166 = <0x00 0x00 0x02 0x00 0x01 0x01>;
		qcom,poll167 = <0x00 0x00 0x02 0x00 0x01 0x01>;
		qcom,poll168 = <0x00 0x00 0x02 0x00 0x01 0x01>;
		qcom,poll169 = <0x00 0x00 0x02 0x00 0x01 0x01>;
		qcom,poll17 = <0x00 0x00 0x02 0x00 0x01 0x01>;
		qcom,poll170 = <0x00 0x00 0x02 0x00 0x01 0x01>;
		qcom,poll171 = <0x00 0x00 0x02 0x00 0x01 0x01>;
		qcom,poll172 = <0x00 0x00 0x02 0x00 0x01 0x01>;
		qcom,poll173 = <0x00 0x00 0x02 0x00 0x01 0x01>;
		qcom,poll174 = <0x00 0x00 0x02 0x00 0x01 0x01>;
		qcom,poll175 = <0x00 0x00 0x02 0x00 0x01 0x01>;
		qcom,poll176 = <0x00 0x00 0x02 0x00 0x01 0x01>;
		qcom,poll177 = <0x00 0x00 0x02 0x00 0x01 0x01>;
		qcom,poll178 = <0x00 0x00 0x02 0x00 0x01 0x01>;
		qcom,poll179 = <0x00 0x00 0x02 0x00 0x01 0x01>;
		qcom,poll18 = <0x00 0x00 0x02 0x00 0x01 0x01>;
		qcom,poll180 = <0x00 0x00 0x02 0x00 0x01 0x01>;
		qcom,poll181 = <0x00 0x00 0x02 0x00 0x01 0x01>;
		qcom,poll182 = <0x00 0x00 0x02 0x00 0x01 0x01>;
		qcom,poll183 = <0x00 0x00 0x02 0x00 0x01 0x01>;
		qcom,poll184 = <0x00 0x00 0x02 0x00 0x01 0x01>;
		qcom,poll185 = <0x00 0x00 0x02 0x00 0x01 0x01>;
		qcom,poll186 = <0x00 0x00 0x02 0x00 0x01 0x01>;
		qcom,poll187 = <0x00 0x00 0x02 0x00 0x01 0x01>;
		qcom,poll188 = <0x00 0x00 0x02 0x00 0x01 0x01>;
		qcom,poll189 = <0x00 0x00 0x02 0x00 0x01 0x01>;
		qcom,poll19 = <0x00 0x00 0x02 0x00 0x01 0x01>;
		qcom,poll190 = <0x00 0x00 0x02 0x00 0x01 0x01>;
		qcom,poll191 = <0x00 0x00 0x02 0x00 0x01 0x01>;
		qcom,poll2 = <0x00 0x00 0x02 0x00 0x01 0x01>;
		qcom,poll20 = <0x00 0x00 0x02 0x00 0x01 0x01>;
		qcom,poll21 = <0x00 0x00 0x02 0x00 0x01 0x01>;
		qcom,poll22 = <0x00 0x00 0x02 0x00 0x01 0x01>;
		qcom,poll23 = <0x00 0x00 0x02 0x00 0x01 0x01>;
		qcom,poll24 = <0x00 0x00 0x02 0x00 0x01 0x01>;
		qcom,poll25 = <0x00 0x00 0x02 0x00 0x01 0x01>;
		qcom,poll26 = <0x00 0x00 0x02 0x00 0x01 0x01>;
		qcom,poll27 = <0x00 0x00 0x02 0x00 0x01 0x01>;
		qcom,poll28 = <0x00 0x00 0x02 0x00 0x01 0x01>;
		qcom,poll29 = <0x00 0x00 0x02 0x00 0x01 0x01>;
		qcom,poll3 = <0x00 0x00 0x02 0x00 0x01 0x01>;
		qcom,poll30 = <0x00 0x00 0x02 0x00 0x01 0x01>;
		qcom,poll31 = <0x00 0x00 0x02 0x00 0x01 0x01>;
		qcom,poll32 = <0x00 0x00 0x02 0x00 0x01 0x01>;
		qcom,poll33 = <0x00 0x00 0x02 0x00 0x01 0x01>;
		qcom,poll34 = <0x00 0x00 0x02 0x00 0x01 0x01>;
		qcom,poll35 = <0x00 0x00 0x02 0x00 0x01 0x01>;
		qcom,poll36 = <0x00 0x00 0x02 0x00 0x01 0x01>;
		qcom,poll37 = <0x00 0x00 0x02 0x00 0x01 0x01>;
		qcom,poll38 = <0x00 0x00 0x02 0x00 0x01 0x01>;
		qcom,poll39 = <0x00 0x00 0x02 0x00 0x01 0x01>;
		qcom,poll4 = <0x00 0x00 0x02 0x00 0x01 0x01>;
		qcom,poll40 = <0x00 0x00 0x02 0x00 0x01 0x01>;
		qcom,poll41 = <0x00 0x00 0x02 0x00 0x01 0x01>;
		qcom,poll42 = <0x00 0x00 0x02 0x00 0x01 0x01>;
		qcom,poll43 = <0x00 0x00 0x02 0x00 0x01 0x01>;
		qcom,poll44 = <0x00 0x00 0x02 0x00 0x01 0x01>;
		qcom,poll45 = <0x00 0x00 0x02 0x00 0x01 0x01>;
		qcom,poll46 = <0x00 0x00 0x02 0x00 0x01 0x01>;
		qcom,poll47 = <0x00 0x00 0x02 0x00 0x01 0x01>;
		qcom,poll48 = <0x00 0x00 0x02 0x00 0x01 0x01>;
		qcom,poll49 = <0x00 0x00 0x02 0x00 0x01 0x01>;
		qcom,poll5 = <0x00 0x00 0x02 0x00 0x01 0x01>;
		qcom,poll50 = <0x00 0x00 0x02 0x00 0x01 0x01>;
		qcom,poll51 = <0x00 0x00 0x02 0x00 0x01 0x01>;
		qcom,poll52 = <0x00 0x00 0x02 0x00 0x01 0x01>;
		qcom,poll53 = <0x00 0x00 0x02 0x00 0x01 0x01>;
		qcom,poll54 = <0x00 0x00 0x02 0x00 0x01 0x01>;
		qcom,poll55 = <0x00 0x00 0x02 0x00 0x01 0x01>;
		qcom,poll56 = <0x00 0x00 0x02 0x00 0x01 0x01>;
		qcom,poll57 = <0x00 0x00 0x02 0x00 0x01 0x01>;
		qcom,poll58 = <0x00 0x00 0x02 0x00 0x01 0x01>;
		qcom,poll59 = <0x00 0x00 0x02 0x00 0x01 0x01>;
		qcom,poll6 = <0x00 0x00 0x02 0x00 0x01 0x01>;
		qcom,poll60 = <0x00 0x00 0x02 0x00 0x01 0x01>;
		qcom,poll61 = <0x00 0x00 0x02 0x00 0x01 0x01>;
		qcom,poll62 = <0x00 0x00 0x02 0x00 0x01 0x01>;
		qcom,poll63 = <0x00 0x00 0x02 0x00 0x01 0x01>;
		qcom,poll64 = <0x00 0x00 0x02 0x00 0x01 0x01>;
		qcom,poll65 = <0x00 0x00 0x02 0x00 0x01 0x01>;
		qcom,poll66 = <0x00 0x00 0x02 0x00 0x01 0x01>;
		qcom,poll67 = <0x00 0x00 0x02 0x00 0x01 0x01>;
		qcom,poll68 = <0x00 0x00 0x02 0x00 0x01 0x01>;
		qcom,poll69 = <0x00 0x00 0x02 0x00 0x01 0x01>;
		qcom,poll7 = <0x00 0x00 0x02 0x00 0x01 0x01>;
		qcom,poll70 = <0x00 0x00 0x02 0x00 0x01 0x01>;
		qcom,poll71 = <0x00 0x00 0x02 0x00 0x01 0x01>;
		qcom,poll72 = <0x00 0x00 0x02 0x00 0x01 0x01>;
		qcom,poll73 = <0x00 0x00 0x02 0x00 0x01 0x01>;
		qcom,poll74 = <0x00 0x00 0x02 0x00 0x01 0x01>;
		qcom,poll75 = <0x00 0x00 0x02 0x00 0x01 0x01>;
		qcom,poll76 = <0x00 0x00 0x02 0x00 0x01 0x01>;
		qcom,poll77 = <0x00 0x00 0x02 0x00 0x01 0x01>;
		qcom,poll78 = <0x00 0x00 0x02 0x00 0x01 0x01>;
		qcom,poll79 = <0x00 0x00 0x02 0x00 0x01 0x01>;
		qcom,poll8 = <0x00 0x00 0x02 0x00 0x01 0x01>;
		qcom,poll80 = <0x00 0x00 0x02 0x00 0x01 0x01>;
		qcom,poll81 = <0x00 0x00 0x02 0x00 0x01 0x01>;
		qcom,poll82 = <0x00 0x00 0x02 0x00 0x01 0x01>;
		qcom,poll83 = <0x00 0x00 0x02 0x00 0x01 0x01>;
		qcom,poll84 = <0x00 0x00 0x02 0x00 0x01 0x01>;
		qcom,poll85 = <0x00 0x00 0x02 0x00 0x01 0x01>;
		qcom,poll86 = <0x00 0x00 0x02 0x00 0x01 0x01>;
		qcom,poll87 = <0x00 0x00 0x02 0x00 0x01 0x01>;
		qcom,poll88 = <0x00 0x00 0x02 0x00 0x01 0x01>;
		qcom,poll89 = <0x00 0x00 0x02 0x00 0x01 0x01>;
		qcom,poll9 = <0x00 0x00 0x02 0x00 0x01 0x01>;
		qcom,poll90 = <0x00 0x00 0x02 0x00 0x01 0x01>;
		qcom,poll91 = <0x00 0x00 0x02 0x00 0x01 0x01>;
		qcom,poll92 = <0x00 0x00 0x02 0x00 0x01 0x01>;
		qcom,poll93 = <0x00 0x00 0x02 0x00 0x01 0x01>;
		qcom,poll94 = <0x00 0x00 0x02 0x00 0x01 0x01>;
		qcom,poll95 = <0x00 0x00 0x02 0x00 0x01 0x01>;
		qcom,poll96 = <0x00 0x00 0x02 0x00 0x01 0x01>;
		qcom,poll97 = <0x00 0x00 0x02 0x00 0x01 0x01>;
		qcom,poll98 = <0x00 0x00 0x02 0x00 0x01 0x01>;
		qcom,poll99 = <0x00 0x00 0x02 0x00 0x01 0x01>;
		qcom,slave-addr = <0x40>;
		reg = <0x40 0x00>;
	};

	eeprom1: qcom,eeprom@6c {
		cam_vana-supply = <&pm8909_l17>;
		cam_vdig-supply = <&pm8909_l2>;
		cam_vio-supply = <&pm8909_l6>;
		cell-index = <0x00>;
		clock-names = "cam_src_clk", "cam_clk";
		clocks = <&clock_gcc clk_mclk0_clk_src>,
				<&clock_gcc clk_gcc_camss_mclk0_clk>;
		compatible = "qcom,eeprom";
		gpios = <&msm_gpio 0x1a 0x00 &msm_gpio 0x23 0x00 &msm_gpio 0x22 0x00 &msm_gpio 0x00 0x00 &msm_gpio 0x01 0x00>;
		pinctrl-0 = <&cam_sensor_mclk0_default
				&cam_sensor_rear_default>;
		pinctrl-1 = <&cam_sensor_mclk0_sleep &cam_sensor_rear_sleep>;
		pinctrl-names = "cam_default", "cam_suspend";
		qcom,cam-power-seq-cfg-val = <0x01 0x01 0x01 0x01 0x16c6140>;
		qcom,cam-power-seq-delay = <0x01 0x0a 0x0a 0x05 0x05>;
		qcom,cam-power-seq-type = "sensor_vreg", "sensor_gpio", "sensor_gpio", "sensor_gpio", "sensor_clk";
		qcom,cam-power-seq-val = "cam_vdig", "sensor_gpio_vana", "sensor_gpio_reset", "sensor_gpio_standby", "sensor_cam_mclk";
		qcom,cam-vreg-max-voltage = <0x124f80 0x00 0x2b7cd0>;
		qcom,cam-vreg-min-voltage = <0x124f80 0x00 0x2b7cd0>;
		qcom,cam-vreg-name = "cam_vdig", "cam_vio", "cam_vana";
		qcom,cam-vreg-op-mode = <0x30d40 0x00 0x13880>;
		qcom,cam-vreg-type = <0x00 0x01 0x00>;
		qcom,cci-master = <0x00>;
		qcom,eeprom-name = "toshiba_t4ka3";
		qcom,gpio-req-tbl-flags = <0x01 0x00 0x00 0x00 0x00>;
		qcom,gpio-req-tbl-label = "CAMIF_MCLK", "CAM_RESET1", "CAM_STANDBY", "CAM_VANA", "CAM_VDIG";
		qcom,gpio-req-tbl-num = <0x00 0x01 0x02 0x03 0x04>;
		qcom,gpio-reset = <0x01>;
		qcom,gpio-standby = <0x02>;
		qcom,gpio-vana = <0x03>;
		qcom,gpio-vdig = <0x04>;
		qcom,mem0 = <0x00 0x00 0x02 0x00 0x01 0x00>;
		qcom,mem1 = <0x00 0x00 0x02 0x00 0x01 0x00>;
		qcom,mem10 = <0x00 0x00 0x02 0x00 0x01 0x00>;
		qcom,mem11 = <0x40 0x4a04 0x02 0x00 0x01 0x00>;
		qcom,mem12 = <0x00 0x00 0x02 0x00 0x01 0x00>;
		qcom,mem13 = <0x00 0x00 0x02 0x00 0x01 0x00>;
		qcom,mem14 = <0x40 0x4a04 0x02 0x00 0x01 0x00>;
		qcom,mem15 = <0x00 0x00 0x02 0x00 0x01 0x00>;
		qcom,mem16 = <0x00 0x00 0x02 0x00 0x01 0x00>;
		qcom,mem17 = <0x40 0x4a04 0x02 0x00 0x01 0x00>;
		qcom,mem18 = <0x00 0x00 0x02 0x00 0x01 0x00>;
		qcom,mem19 = <0x00 0x00 0x02 0x00 0x01 0x00>;
		qcom,mem2 = <0x40 0x4a04 0x02 0x00 0x01 0x00>;
		qcom,mem20 = <0x40 0x4a04 0x02 0x00 0x01 0x00>;
		qcom,mem21 = <0x00 0x00 0x02 0x00 0x01 0x00>;
		qcom,mem22 = <0x00 0x00 0x02 0x00 0x01 0x00>;
		qcom,mem23 = <0x40 0x4a04 0x02 0x00 0x01 0x00>;
		qcom,mem3 = <0x00 0x00 0x02 0x00 0x01 0x00>;
		qcom,mem4 = <0x00 0x00 0x02 0x00 0x01 0x00>;
		qcom,mem5 = <0x40 0x4a04 0x02 0x00 0x01 0x00>;
		qcom,mem6 = <0x00 0x00 0x02 0x00 0x01 0x00>;
		qcom,mem7 = <0x00 0x00 0x02 0x00 0x01 0x00>;
		qcom,mem8 = <0x40 0x4a04 0x02 0x00 0x01 0x00>;
		qcom,mem9 = <0x00 0x00 0x02 0x00 0x01 0x00>;
		qcom,num-blocks = <0x18>;
		qcom,page0 = <0x01 0x4a00 0x02 0x01 0x01 0x01>;
		qcom,page1 = <0x01 0x4a02 0x02 0x00 0x01 0x01>;
		qcom,page10 = <0x01 0x4a02 0x02 0x03 0x01 0x01>;
		qcom,page11 = <0x01 0x4a00 0x02 0x81 0x01 0x01>;
		qcom,page12 = <0x01 0x4a00 0x02 0x01 0x01 0x01>;
		qcom,page13 = <0x01 0x4a02 0x02 0x04 0x01 0x01>;
		qcom,page14 = <0x01 0x4a00 0x02 0x81 0x01 0x01>;
		qcom,page15 = <0x01 0x4a00 0x02 0x01 0x01 0x01>;
		qcom,page16 = <0x01 0x4a02 0x02 0x05 0x01 0x01>;
		qcom,page17 = <0x01 0x4a00 0x02 0x81 0x01 0x01>;
		qcom,page18 = <0x01 0x4a00 0x02 0x01 0x01 0x01>;
		qcom,page19 = <0x01 0x4a02 0x02 0x06 0x01 0x01>;
		qcom,page2 = <0x01 0x4a00 0x02 0x81 0x01 0x01>;
		qcom,page20 = <0x01 0x4a00 0x02 0x81 0x01 0x01>;
		qcom,page21 = <0x01 0x4a00 0x02 0x01 0x01 0x01>;
		qcom,page22 = <0x01 0x4a02 0x02 0x07 0x01 0x01>;
		qcom,page23 = <0x01 0x4a00 0x02 0x81 0x01 0x01>;
		qcom,page3 = <0x01 0x4a00 0x02 0x01 0x01 0x01>;
		qcom,page4 = <0x01 0x4a02 0x02 0x01 0x01 0x01>;
		qcom,page5 = <0x01 0x4a00 0x02 0x81 0x01 0x01>;
		qcom,page6 = <0x01 0x4a00 0x02 0x01 0x01 0x01>;
		qcom,page7 = <0x01 0x4a02 0x02 0x02 0x01 0x01>;
		qcom,page8 = <0x01 0x4a00 0x02 0x81 0x01 0x01>;
		qcom,page9 = <0x01 0x4a00 0x02 0x01 0x01 0x01>;
		qcom,poll0 = <0x00 0x00 0x02 0x00 0x01 0x01>;
		qcom,poll1 = <0x00 0x00 0x02 0x00 0x01 0x01>;
		qcom,poll10 = <0x00 0x00 0x02 0x00 0x01 0x01>;
		qcom,poll11 = <0x00 0x00 0x02 0x00 0x01 0x01>;
		qcom,poll12 = <0x00 0x00 0x02 0x00 0x01 0x01>;
		qcom,poll13 = <0x00 0x00 0x02 0x00 0x01 0x01>;
		qcom,poll14 = <0x00 0x00 0x02 0x00 0x01 0x01>;
		qcom,poll15 = <0x00 0x00 0x02 0x00 0x01 0x01>;
		qcom,poll16 = <0x00 0x00 0x02 0x00 0x01 0x01>;
		qcom,poll17 = <0x00 0x00 0x02 0x00 0x01 0x01>;
		qcom,poll18 = <0x00 0x00 0x02 0x00 0x01 0x01>;
		qcom,poll19 = <0x00 0x00 0x02 0x00 0x01 0x01>;
		qcom,poll2 = <0x00 0x00 0x02 0x00 0x01 0x01>;
		qcom,poll20 = <0x00 0x00 0x02 0x00 0x01 0x01>;
		qcom,poll21 = <0x00 0x00 0x02 0x00 0x01 0x01>;
		qcom,poll22 = <0x00 0x00 0x02 0x00 0x01 0x01>;
		qcom,poll23 = <0x00 0x00 0x02 0x00 0x01 0x01>;
		qcom,poll3 = <0x00 0x00 0x02 0x00 0x01 0x01>;
		qcom,poll4 = <0x00 0x00 0x02 0x00 0x01 0x01>;
		qcom,poll5 = <0x00 0x00 0x02 0x00 0x01 0x01>;
		qcom,poll6 = <0x00 0x00 0x02 0x00 0x01 0x01>;
		qcom,poll7 = <0x00 0x00 0x02 0x00 0x01 0x01>;
		qcom,poll8 = <0x00 0x00 0x02 0x00 0x01 0x01>;
		qcom,poll9 = <0x00 0x00 0x02 0x00 0x01 0x01>;
		qcom,slave-addr = <0x6c>;
		reg = <0x6c>;
	};

	qcom,camera@0 {
		cam_vaf-supply = <&pm8909_l8>;
		cam_vdig-supply = <&pm8909_l2>;
		cam_vana-supply = <&pm8909_l17>;
		cam_vio-supply = <&pm8909_l6>;
		cell-index = <0x00>;
		clock-names = "cam_src_clk", "cam_clk";
		clocks = <&clock_gcc clk_mclk0_clk_src>,
				<&clock_gcc clk_gcc_camss_mclk0_clk>;
		compatible = "qcom,camera";
		gpios = <&msm_gpio 0x1a 0x00 &msm_gpio 0x23 0x00 &msm_gpio 0x22 0x00 &msm_gpio 0x00 0x00 &msm_gpio 0x01 0x00>;
		pinctrl-0 = <&cam_sensor_mclk0_default
				&cam_sensor_rear_default>;
		pinctrl-1 = <&cam_sensor_mclk0_sleep &cam_sensor_rear_sleep>;
		pinctrl-names = "cam_default", "cam_suspend";
		qcom,actuator-src = <&actuator>;
		qcom,cam-vreg-max-voltage = <0x124f80 0x00 0x2b7cd0 0x2c4020>;
		qcom,cam-vreg-min-voltage = <0x124f80 0x00 0x2b7cd0 0x2b7cd0>;
		qcom,cam-vreg-name = "cam_vdig", "cam_vio", "cam_vana", "cam_vaf";
		qcom,cam-vreg-op-mode = <0x30d40 0x00 0x13880 0x186a0>;
		qcom,cam-vreg-type = <0x00 0x01 0x00 0x00>;
		qcom,cci-master = <0x00>;
		qcom,csid-sd-index = <0x00>;
		qcom,csiphy-sd-index = <0x00>;
		qcom,eeprom-src = <&eeprom0 &eeprom1>;
		qcom,gpio-req-tbl-flags = <0x01 0x00 0x00 0x00 0x00>;
		qcom,gpio-req-tbl-label = "CAMIF_MCLK", "CAM_RESET1", "CAM_STANDBY", "CAM_VANA", "CAM_VDIG";
		qcom,gpio-req-tbl-num = <0x00 0x01 0x02 0x03 0x04>;
		qcom,gpio-reset = <0x01>;
		qcom,gpio-standby = <0x02>;
		qcom,gpio-vana = <0x03>;
		qcom,gpio-vdig = <0x04>;
		qcom,led-flash-src = <&led_flash0>;
		qcom,mount-angle = <0x5a>;
		qcom,sensor-mode = <0x00>;
		qcom,sensor-position = <0x00>;
		reg = <0x02>;
		status = "ok";
	};

	qcom,camera@1 {
		cam_vana-supply = <&pm8909_l17>;
		cam_vio-supply = <&pm8909_l6>;
		cell-index = <0x01>;
		clock-names = "cam_src_clk", "cam_clk";
		clocks = <&clock_gcc clk_mclk1_clk_src>,
				<&clock_gcc clk_gcc_camss_mclk1_clk>;
		compatible = "qcom,camera";
		gpios = <&msm_gpio 0x1b 0x00 &msm_gpio 0x1c 0x00 &msm_gpio 0x00 0x00 &msm_gpio 0x21 0x00>;
		pinctrl-0 = <&cam_sensor_mclk1_default &cam_sensor_front_default>;
		pinctrl-1 = <&cam_sensor_mclk1_sleep &cam_sensor_front_sleep>;
		pinctrl-names = "cam_default", "cam_suspend";
		qcom,cam-vreg-max-voltage = <0x00 0x2b7cd0>;
		qcom,cam-vreg-min-voltage = <0x00 0x2b7cd0>;
		qcom,cam-vreg-name = "cam_vio", "cam_vana";
		qcom,cam-vreg-op-mode = <0x00 0x13880>;
		qcom,cam-vreg-type = <0x01 0x00>;
		qcom,cci-master = <0x00>;
		qcom,csid-sd-index = <0x00>;
		qcom,csiphy-sd-index = <0x00>;
		qcom,gpio-req-tbl-flags = <0x01 0x00 0x00 0x00>;
		qcom,gpio-req-tbl-label = "CAMIF_MCLK", "CAM_RESET", "CAM_VANA", "CAM_STANDBY";
		qcom,gpio-req-tbl-num = <0x00 0x01 0x02 0x03>;
		qcom,gpio-reset = <0x01>;
		qcom,gpio-standby = <0x03>;
		qcom,gpio-vana = <0x02>;
		qcom,mount-angle = <0x5a>;
		reg = <0x01>;
		status = "ok";
	};

	qcom,camera@43 {
		cam_vana-supply = <&pm8909_l17>;
		cam_vio-supply = <&pm8909_l6>;
		clock-names = "cam_src_clk", "cam_clk";
		clocks = <&clock_gcc clk_mclk1_clk_src>,
				<&clock_gcc clk_gcc_camss_mclk1_clk>;
		compatible = "qcom,sp0a20";
		gpios = <&msm_gpio 0x1b 0x00 &msm_gpio 0x1c 0x00 &msm_gpio 0x00 0x00 &msm_gpio 0x21 0x00>;
		pinctrl-0 = <&cam_sensor_mclk1_default &cam_sensor_front_default>;
		pinctrl-1 = <&cam_sensor_mclk1_sleep &cam_sensor_front_sleep>;
		pinctrl-names = "cam_default", "cam_suspend";
		qcom,cam-vreg-max-voltage = <0x00 0x2b7cd0>;
		qcom,cam-vreg-min-voltage = <0x00 0x2ab980>;
		qcom,cam-vreg-name = "cam_vio", "cam_vana";
		qcom,cam-vreg-op-mode = <0x00 0x13880>;
		qcom,cam-vreg-type = <0x01 0x00>;
		qcom,cci-master = <0x00>;
		qcom,csi-lane-assign = <0x04>;
		qcom,csi-lane-mask = <0x18>;
		qcom,csid-sd-index = <0x00>;
		qcom,csiphy-sd-index = <0x00>;
		qcom,gpio-req-tbl-flags = <0x01 0x00 0x00 0x00>;
		qcom,gpio-req-tbl-label = "CAMIF_MCLK", "CAM_RESET", "CAM_VANA", "CAM_STANDBY";
		qcom,gpio-req-tbl-num = <0x00 0x01 0x02 0x03>;
		qcom,gpio-reset = <0x01>;
		qcom,gpio-set-tbl-delay = <0x3e8 0xfa0>;
		qcom,gpio-set-tbl-flags = <0x00 0x02>;
		qcom,gpio-set-tbl-num = <0x01 0x01>;
		qcom,gpio-standby = <0x03>;
		qcom,gpio-vana = <0x02>;
		qcom,mount-angle = <0x10e>;
		qcom,sensor-mode = <0x01>;
		qcom,sensor-name = "sp0a20_8909";
		qcom,sensor-position = <0x01>;
		qcom,slave-id = <0x42 0x01 0xa2b>;
		reg = <0x43>;
	};
};
